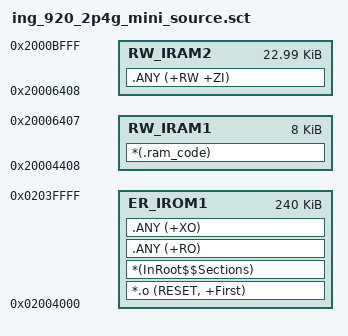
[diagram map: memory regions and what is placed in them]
; *************************************************************
; *** Scatter-Loading Description File generated by uVision ***
; *************************************************************

LR_IROM1 0x2004000 0x3C000  {    ; load region size_region
  ER_IROM1 0x2004000 0x3C000  {  ; load address = execution address
   *.o (RESET, +First)
   *(InRoot$$Sections)
   .ANY (+RO)
   .ANY (+XO)
  }
  RW_IRAM1 0x20004408 0x00002000  {  ; RW data
   *(.ram_code)
  }
  RW_IRAM2 0x20006408 0x5BF8  {  ; RW data
   .ANY (+RW +ZI)
  }
}

